# STM32F101 register map
File version: 1.2
CPU: CM3 r1p1, little endian, no MPU, no FPU, 4 interrupt priority bits
Registers are 32-bit, read-write, reset 0x0 unless marked. A register's access mark holds for its fields unless they carry their own. Offsets are from the block's base; [hi:lo] are bit positions; {n}, {i} and the like mark numbered series.

## DAC — Digital to analog converter
Base 0x40007400
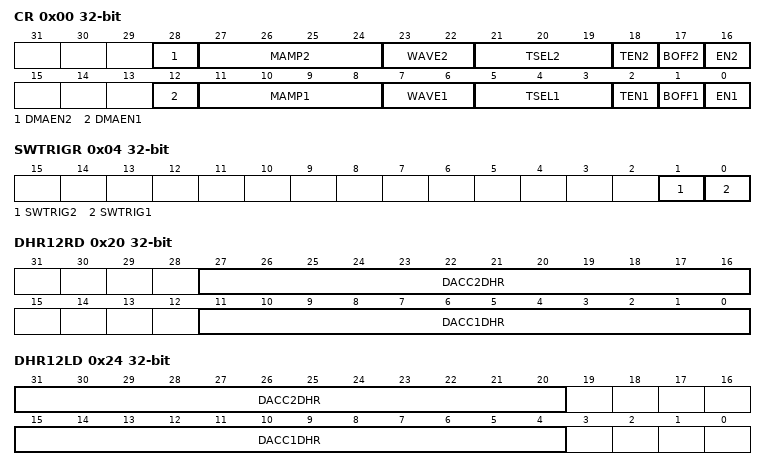
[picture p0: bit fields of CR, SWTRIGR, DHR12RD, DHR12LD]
0x00 CR — Control register (DAC_CR)
  [28] DMAEN2 — DAC channel2 DMA enable
  [27:24] MAMP2 — DAC channel2 mask/amplitude selector
  [23:22] WAVE2 — DAC channel2 noise/triangle wave generation enable
  [21:19] TSEL2 — DAC channel2 trigger selection
  [18] TEN2 — DAC channel2 trigger enable
  [17] BOFF2 — DAC channel2 output buffer disable
  [16] EN2 — DAC channel2 enable
  [12] DMAEN1 — DAC channel1 DMA enable
  [11:8] MAMP1 — DAC channel1 mask/amplitude selector
  [7:6] WAVE1 — DAC channel1 noise/triangle wave generation enable
  [5:3] TSEL1 — DAC channel1 trigger selection
  [2] TEN1 — DAC channel1 trigger enable
  [1] BOFF1 — DAC channel1 output buffer disable
  [0] EN1 — DAC channel1 enable
0x04 SWTRIGR wo — DAC software trigger register (DAC_SWTRIGR)
  [1] SWTRIG2 — DAC channel2 software trigger
  [0] SWTRIG1 — DAC channel1 software trigger
0x08 DHR12R1 — DAC channel1 12-bit right-aligned data holding register(DAC_DHR12R1)
  [11:0] DACC1DHR — DAC channel1 12-bit right-aligned data
0x0C DHR12L1 — DAC channel1 12-bit left aligned data holding register (DAC_DHR12L1)
  [15:4] DACC1DHR — DAC channel1 12-bit left-aligned data
0x10 DHR8R1 — DAC channel1 8-bit right aligned data holding register (DAC_DHR8R1)
  [7:0] DACC1DHR — DAC channel1 8-bit right-aligned data
0x14 DHR12R2 — DAC channel2 12-bit right aligned data holding register (DAC_DHR12R2)
  [11:0] DACC2DHR — DAC channel2 12-bit right-aligned data
0x18 DHR12L2 — DAC channel2 12-bit left aligned data holding register (DAC_DHR12L2)
  [15:4] DACC2DHR — DAC channel2 12-bit left-aligned data
0x1C DHR8R2 — DAC channel2 8-bit right-aligned data holding register (DAC_DHR8R2)
  [7:0] DACC2DHR — DAC channel2 8-bit right-aligned data
0x20 DHR12RD — Dual DAC 12-bit right-aligned data holding register (DAC_DHR12RD), Bits 31:28 Reserved, Bits 15:12 Reserved
  [27:16] DACC2DHR — DAC channel2 12-bit right-aligned data
  [11:0] DACC1DHR — DAC channel1 12-bit right-aligned data
0x24 DHR12LD — DUAL DAC 12-bit left aligned data holding register (DAC_DHR12LD), Bits 19:16 Reserved, Bits 3:0 Reserved
  [31:20] DACC2DHR — DAC channel2 12-bit right-aligned data
  [15:4] DACC1DHR — DAC channel1 12-bit left-aligned data
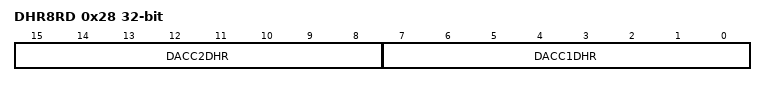
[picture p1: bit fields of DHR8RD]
0x28 DHR8RD — DUAL DAC 8-bit right aligned data holding register (DAC_DHR8RD), Bits 31:16 Reserved
  [15:8] DACC2DHR — DAC channel2 8-bit right-aligned data
  [7:0] DACC1DHR — DAC channel1 8-bit right-aligned data
0x2C DOR1 ro — DAC channel1 data output register (DAC_DOR1)
  [11:0] DACC1DOR — DAC channel1 data output
0x30 DOR2 ro — DAC channel2 data output register (DAC_DOR2)
  [11:0] DACC2DOR — DAC channel2 data output

## DBG — Debug support
Base 0xE0042000
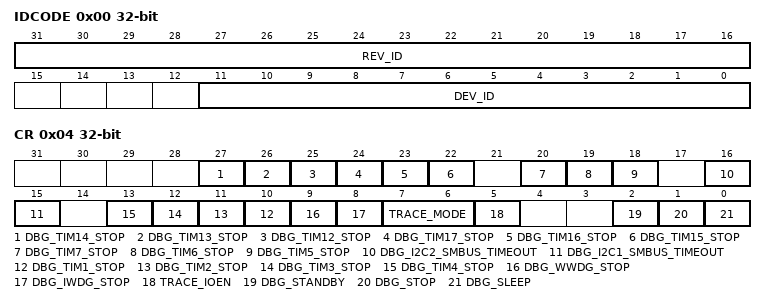
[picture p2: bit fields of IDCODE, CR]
0x00 IDCODE ro — DBGMCU_IDCODE
  [31:16] REV_ID, [11:0] DEV_ID
0x04 CR — DBGMCU_CR
  [27] DBG_TIM14_STOP — TIM14 counter stopped when core is halted
  [26] DBG_TIM13_STOP — TIM13 counter stopped when core is halted
  [25] DBG_TIM12_STOP — TIM12 counter stopped when core is halted
  [24] DBG_TIM17_STOP — TIM17 counter stopped when core is halted
  [23] DBG_TIM16_STOP — TIM16 counter stopped when core is halted
  [22] DBG_TIM15_STOP — TIM15 counter stopped when core is halted
  [20] DBG_TIM7_STOP
  [19] DBG_TIM6_STOP
  [18] DBG_TIM5_STOP
  [16] DBG_I2C2_SMBUS_TIMEOUT
  [15] DBG_I2C1_SMBUS_TIMEOUT
  [n+9] DBG_TIM{n}_STOP (n=1..4)
  [9] DBG_WWDG_STOP
  [8] DBG_IWDG_STOP
  [7:6] TRACE_MODE
  [5] TRACE_IOEN
  [2] DBG_STANDBY
  [1] DBG_STOP
  [0] DBG_SLEEP

## UART4 — Universal asynchronous receiver transmitter
Base 0x40004C00
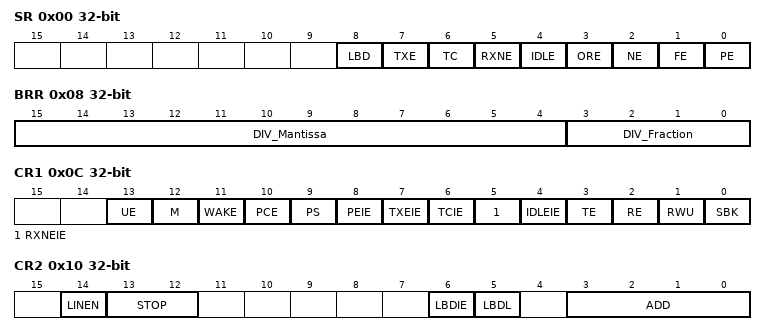
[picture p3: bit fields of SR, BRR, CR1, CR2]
0x00 SR access per field — UART4_SR
  [8] LBD rw — LIN break detection flag
  [7] TXE ro — Transmit data register empty
  [6] TC rw — Transmission complete
  [5] RXNE rw — Read data register not empty
  [4] IDLE ro — IDLE line detected
  [3] ORE ro — Overrun error
  [2] NE ro — Noise error flag
  [1] FE ro — Framing error
  [0] PE ro — Parity error
0x04 DR — UART4_DR
  [8:0] DR
0x08 BRR — UART4_BRR
  [15:4] DIV_Mantissa, [3:0] DIV_Fraction
0x0C CR1 — UART4_CR1
  [13] UE — USART enable
  [12] M — Word length
  [11] WAKE — Wakeup method
  [10] PCE — Parity control enable
  [9] PS — Parity selection
  [8] PEIE — PE interrupt enable
  [7] TXEIE — TXE interrupt enable
  [6] TCIE — Transmission complete interrupt enable
  [5] RXNEIE — RXNE interrupt enable
  [4] IDLEIE — IDLE interrupt enable
  [3] TE — Transmitter enable
  [2] RE — Receiver enable
  [1] RWU — Receiver wakeup
  [0] SBK — Send break
0x10 CR2 — UART4_CR2
  [14] LINEN — LIN mode enable
  [13:12] STOP — STOP bits
  [6] LBDIE — LIN break detection interrupt enable
  [5] LBDL — lin break detection length
  [3:0] ADD — Address of the USART node
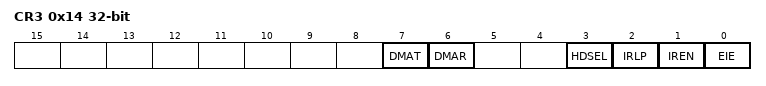
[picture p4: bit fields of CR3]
0x14 CR3 — UART4_CR3
  [7] DMAT — DMA enable transmitter
  [6] DMAR — DMA enable receiver
  [3] HDSEL — Half-duplex selection
  [2] IRLP — IrDA low-power
  [1] IREN — IrDA mode enable
  [0] EIE — Error interrupt enable
